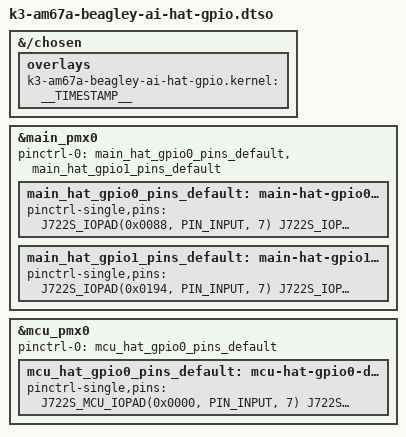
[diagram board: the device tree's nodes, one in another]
/dts-v1/;
/plugin/;

#include <dt-bindings/gpio/gpio.h>
#include "k3-pinctrl.h"

&{/chosen} {
	overlays {
		k3-am67a-beagley-ai-hat-gpio.kernel = __TIMESTAMP__;
	};
};

&main_pmx0 {
	pinctrl-names = "default";
	pinctrl-0 = <&main_hat_gpio0_pins_default>, <&main_hat_gpio1_pins_default>;

	main_hat_gpio0_pins_default: main-hat-gpio0-default-pins {
		pinctrl-single,pins = <
			J722S_IOPAD(0x0088, PIN_INPUT, 7) /* (N22) GPMC0_OEn_REn.GPIO0_33 */
			J722S_IOPAD(0x0094, PIN_INPUT, 7) /* (P26) GPMC0_BE1n.GPIO0_36 */
			J722S_IOPAD(0x009c, PIN_INPUT, 7) /* (W26) GPMC0_WAIT1.GPIO0_38 */
			J722S_IOPAD(0x00a8, PIN_INPUT, 7) /* (R27) GPMC0_CSn0.GPIO0_41 */
			J722S_IOPAD(0x00ac, PIN_INPUT, 7) /* (P21) GPMC0_CSn1.GPIO0_42 */
		>;
	};
	main_hat_gpio1_pins_default: main-hat-gpio1-default-pins {
		pinctrl-single,pins = <
			J722S_IOPAD(0x0194, PIN_INPUT, 7) /* (A25) MCASP0_AXR3.GPIO1_7 */
			J722S_IOPAD(0x0198, PIN_INPUT, 7) /* (A26) MCASP0_AXR2.GPIO1_8 */
			J722S_IOPAD(0x019c, PIN_INPUT, 7) /* (B25) MCASP0_AXR1.GPIO1_9 */
			J722S_IOPAD(0x01a0, PIN_INPUT, 7) /* (F23) MCASP0_AXR0.GPIO1_10 */
			J722S_IOPAD(0x01a4, PIN_INPUT, 7) /* (D25) MCASP0_ACLKX.GPIO1_11 */
			J722S_IOPAD(0x01a8, PIN_INPUT, 7) /* (C26) MCASP0_AFSX.GPIO1_12 */
			J722S_IOPAD(0x01ac, PIN_INPUT, 7) /* (C27) MCASP0_AFSR.GPIO1_13 */
			J722S_IOPAD(0x01b0, PIN_INPUT, 7) /* (F24) MCASP0_ACLKR.GPIO1_14 */
			J722S_IOPAD(0x01b4, PIN_INPUT, 7) /* (B20) SPI0_CS0.GPIO1_15 */
			J722S_IOPAD(0x01b8, PIN_INPUT, 7) /* (C20) SPI0_CS1.GPIO1_16 */
			J722S_IOPAD(0x01bc, PIN_INPUT, 7) /* (D20) SPI0_CLK.GPIO1_17 */
			J722S_IOPAD(0x01c0, PIN_INPUT, 7) /* (E19) SPI0_D0.GPIO1_18 */
		>;
	};
};

&mcu_pmx0 {
	pinctrl-names = "default";
	pinctrl-0 = <&mcu_hat_gpio0_pins_default>;

	mcu_hat_gpio0_pins_default: mcu-hat-gpio0-default-pins {
		pinctrl-single,pins = <
			J722S_MCU_IOPAD(0x0000, PIN_INPUT, 7) /* (C12) MCU_SPI0_CS0.MCU_GPIO0_0 */
			J722S_MCU_IOPAD(0x0008, PIN_INPUT, 7) /* (A9) MCU_SPI0_CLK.MCU_GPIO0_2 */
			J722S_MCU_IOPAD(0x000c, PIN_INPUT, 7) /* (B12) MCU_SPI0_D0.MCU_GPIO0_3 */
			J722S_MCU_IOPAD(0x0010, PIN_INPUT, 7) /* (C11) MCU_SPI0_D1.MCU_GPIO0_4 */
			J722S_MCU_IOPAD(0x001c, PIN_INPUT, 7) /* (B5) MCU_UART0_CTSn.MCU_GPIO0_7 */
			J722S_MCU_IOPAD(0x0024, PIN_INPUT, 7) /* (B3) WKUP_UART0_RXD.MCU_GPIO0_9 */
			J722S_MCU_IOPAD(0x0028, PIN_INPUT, 7) /* (C8) WKUP_UART0_TXD.MCU_GPIO0_10 */
			// Normally /dev/i2c-1
			//J722S_MCU_IOPAD(0x0044, PIN_INPUT, 7) /* (B13) MCU_I2C0_SCL.MCU_GPIO0_17 */
			//J722S_MCU_IOPAD(0x0048, PIN_INPUT, 7) /* (E11) MCU_I2C0_SDA.MCU_GPIO0_18 */
		>;
	};
};
